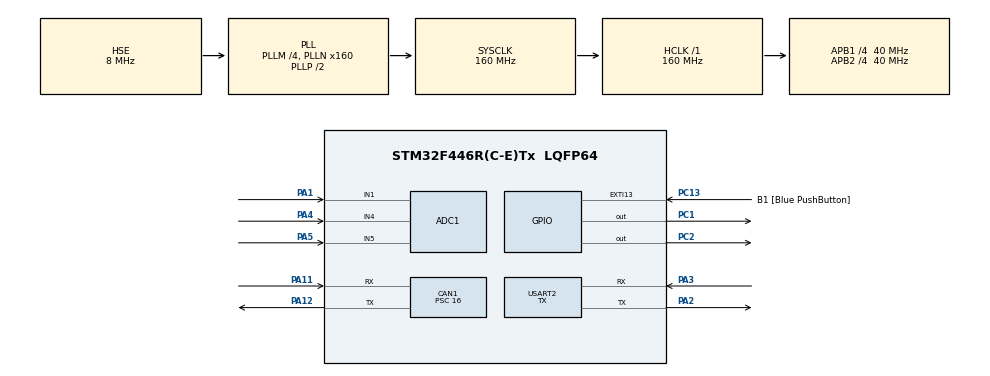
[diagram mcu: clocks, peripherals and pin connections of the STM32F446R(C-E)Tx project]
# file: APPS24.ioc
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ADC1.Channel-0\#ChannelRegularConversion=ADC_CHANNEL_1
ADC1.NbrOfConversionFlag=1
ADC1.Rank-0\#ChannelRegularConversion=1
ADC1.SamplingTime-0\#ChannelRegularConversion=ADC_SAMPLETIME_3CYCLES
ADC1.master=1
CAN1.BS1=CAN_BS1_1TQ
CAN1.BS2=CAN_BS2_2TQ
CAN1.CalculateBaudRate=625000
CAN1.CalculateTimeBit=1600
CAN1.CalculateTimeQuantum=400.0
CAN1.Prescaler=16
Mcu.Family=STM32F4
Mcu.Name=STM32F446R(C-E)Tx
Mcu.Package=LQFP64
NVIC.CAN1_RX0_IRQn=true\:0\:0\:false\:false\:true\:true\:true\:true
NVIC.CAN1_RX1_IRQn=true\:0\:0\:false\:false\:true\:true\:true\:true
NVIC.PriorityGroup=NVIC_PRIORITYGROUP_4
PA1.Signal=ADCx_IN1
PA11.Mode=CAN_Activate
PA11.Signal=CAN1_RX
PA12.Mode=CAN_Activate
PA12.Signal=CAN1_TX
PA13.Mode=Serial_Wire
PA13.Signal=SYS_JTMS-SWDIO
PA14.Mode=Serial_Wire
PA14.Signal=SYS_JTCK-SWCLK
PA2.Mode=Asynchronous
PA2.Signal=USART2_TX
PA3.Mode=Asynchronous
PA3.Signal=USART2_RX
PA4.Signal=ADCx_IN4
PA5.Signal=ADCx_IN5
PC1.Signal=GPIO_Output
PC13.GPIO_Label=B1 [Blue PushButton]
PC13.Signal=GPXTI13
PC14-OSC32_IN.Mode=LSE-External-Oscillator
PC14-OSC32_IN.Signal=RCC_OSC32_IN
PC15-OSC32_OUT.Mode=LSE-External-Oscillator
PC15-OSC32_OUT.Signal=RCC_OSC32_OUT
PC2.Signal=GPIO_Output
PH0-OSC_IN.Mode=HSE-External-Oscillator
PH0-OSC_IN.Signal=RCC_OSC_IN
PH1-OSC_OUT.Mode=HSE-External-Oscillator
PH1-OSC_OUT.Signal=RCC_OSC_OUT
ProjectManager.HeapSize=0x200
ProjectManager.StackSize=0x400
ProjectManager.TargetToolchain=STM32CubeIDE
RCC.AHBFreq_Value=160000000
RCC.APB1CLKDivider=RCC_HCLK_DIV4
RCC.APB1Freq_Value=40000000
RCC.APB1TimFreq_Value=80000000
RCC.APB2CLKDivider=RCC_HCLK_DIV4
RCC.APB2Freq_Value=40000000
RCC.APB2TimFreq_Value=80000000
RCC.CortexFreq_Value=160000000
RCC.HCLKFreq_Value=160000000
RCC.HSE_VALUE=8000000
RCC.PLLM=4
RCC.PLLN=160
RCC.PLLSourceVirtual=RCC_PLLSOURCE_HSE
RCC.SYSCLKFreq_VALUE=160000000
RCC.SYSCLKSource=RCC_SYSCLKSOURCE_PLLCLK
RCC.USBFreq_Value=160000000
RCC.VCOOutputFreq_Value=320000000
SH.ADCx_IN1.0=ADC1_IN1,IN1
SH.ADCx_IN4.0=ADC1_IN4,IN4
SH.ADCx_IN5.0=ADC1_IN5,IN5
USART2.Mode=MODE_TX
USART2.Parity=PARITY_EVEN
USART2.VirtualMode=VM_ASYNC
VP_TIM5_VS_ClockSourceINT.Mode=Internal
board=custom

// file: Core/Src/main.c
/* USER CODE BEGIN Header */
/**
  ******************************************************************************
  * @file           : main.c
  * @brief          : Main program body
  ******************************************************************************
  * @attention
  *
  * Copyright (c) 2023 STMicroelectronics.
  * All rights reserved.
  *
  * This software is licensed under terms that can be found in the LICENSE file
  * in the root directory of this software component.
  * If no LICENSE file comes with this software, it is provided AS-IS.
  *
  ******************************************************************************
  */
/* USER CODE END Header */
#include "main.h"

ADC_HandleTypeDef hadc1;

CAN_HandleTypeDef hcan1;

TIM_HandleTypeDef htim5;

UART_HandleTypeDef huart2;

void SystemClock_Config(void);
static void MX_GPIO_Init(void);
static void MX_USART2_UART_Init(void);
static void MX_CAN1_Init(void);
static void MX_ADC1_Init(void);
static void MX_TIM5_Init(void);

int main(void)
{

  /* MCU Configuration--------------------------------------------------------*/

  /* Reset of all peripherals, Initializes the Flash interface and the Systick. */
  HAL_Init();

  /* Configure the system clock */
  SystemClock_Config();

  /* Initialize all configured peripherals */
  MX_GPIO_Init();
  MX_USART2_UART_Init();
  MX_CAN1_Init();
  MX_ADC1_Init();
  MX_TIM5_Init();
  /* USER CODE BEGIN 2 */
  FEB_Main_User2();
  /* USER CODE END 2 */

  /* Infinite loop */
  while (1)
  {

    /* USER CODE BEGIN 3 */
	//ready to drive
	FEB_Main_User3();
  }
  /* USER CODE END 3 */
}

void SystemClock_Config(void)
{
  RCC_OscInitTypeDef RCC_OscInitStruct = {0};
  RCC_ClkInitTypeDef RCC_ClkInitStruct = {0};

  /** Configure the main internal regulator output voltage
  */
  __HAL_RCC_PWR_CLK_ENABLE();
  __HAL_PWR_VOLTAGESCALING_CONFIG(PWR_REGULATOR_VOLTAGE_SCALE1);

  /** Initializes the RCC Oscillators according to the specified parameters
  * in the RCC_OscInitTypeDef structure.
  */
  RCC_OscInitStruct.OscillatorType = RCC_OSCILLATORTYPE_HSE;
  RCC_OscInitStruct.HSEState = RCC_HSE_ON;
  RCC_OscInitStruct.PLL.PLLState = RCC_PLL_ON;
  RCC_OscInitStruct.PLL.PLLSource = RCC_PLLSOURCE_HSE;
  RCC_OscInitStruct.PLL.PLLM = 4;
  RCC_OscInitStruct.PLL.PLLN = 160;
  RCC_OscInitStruct.PLL.PLLP = RCC_PLLP_DIV2;
  RCC_OscInitStruct.PLL.PLLQ = 2;
  RCC_OscInitStruct.PLL.PLLR = 2;
  if (HAL_RCC_OscConfig(&RCC_OscInitStruct) != HAL_OK)
  {
    Error_Handler();
  }

  /** Initializes the CPU, AHB and APB buses clocks
  */
  RCC_ClkInitStruct.ClockType = RCC_CLOCKTYPE_HCLK|RCC_CLOCKTYPE_SYSCLK
                              |RCC_CLOCKTYPE_PCLK1|RCC_CLOCKTYPE_PCLK2;
  RCC_ClkInitStruct.SYSCLKSource = RCC_SYSCLKSOURCE_PLLCLK;
  RCC_ClkInitStruct.AHBCLKDivider = RCC_SYSCLK_DIV1;
  RCC_ClkInitStruct.APB1CLKDivider = RCC_HCLK_DIV4;
  RCC_ClkInitStruct.APB2CLKDivider = RCC_HCLK_DIV4;

  if (HAL_RCC_ClockConfig(&RCC_ClkInitStruct, FLASH_LATENCY_5) != HAL_OK)
  {
    Error_Handler();
  }
}

static void MX_ADC1_Init(void)
{

  ADC_ChannelConfTypeDef sConfig = {0};

  /** Configure the global features of the ADC (Clock, Resolution, Data Alignment and number of conversion)
  */
  hadc1.Instance = ADC1;
  hadc1.Init.ClockPrescaler = ADC_CLOCK_SYNC_PCLK_DIV2;
  hadc1.Init.Resolution = ADC_RESOLUTION_12B;
  hadc1.Init.ScanConvMode = DISABLE;
  hadc1.Init.ContinuousConvMode = DISABLE;
  hadc1.Init.DiscontinuousConvMode = DISABLE;
  hadc1.Init.ExternalTrigConvEdge = ADC_EXTERNALTRIGCONVEDGE_NONE;
  hadc1.Init.ExternalTrigConv = ADC_SOFTWARE_START;
  hadc1.Init.DataAlign = ADC_DATAALIGN_RIGHT;
  hadc1.Init.NbrOfConversion = 1;
  hadc1.Init.DMAContinuousRequests = DISABLE;
  hadc1.Init.EOCSelection = ADC_EOC_SINGLE_CONV;
  if (HAL_ADC_Init(&hadc1) != HAL_OK)
  {
    Error_Handler();
  }

  /** Configure for the selected ADC regular channel its corresponding rank in the sequencer and its sample time.
  */
  sConfig.Channel = ADC_CHANNEL_1;
  sConfig.Rank = 1;
  sConfig.SamplingTime = ADC_SAMPLETIME_3CYCLES;
  if (HAL_ADC_ConfigChannel(&hadc1, &sConfig) != HAL_OK)
  {
    Error_Handler();
  }

}

static void MX_CAN1_Init(void)
{

  hcan1.Instance = CAN1;
  hcan1.Init.Prescaler = 16;
  hcan1.Init.Mode = CAN_MODE_NORMAL;
  hcan1.Init.SyncJumpWidth = CAN_SJW_1TQ;
  hcan1.Init.TimeSeg1 = CAN_BS1_1TQ;
  hcan1.Init.TimeSeg2 = CAN_BS2_2TQ;
  hcan1.Init.TimeTriggeredMode = DISABLE;
  hcan1.Init.AutoBusOff = DISABLE;
  hcan1.Init.AutoWakeUp = DISABLE;
  hcan1.Init.AutoRetransmission = DISABLE;
  hcan1.Init.ReceiveFifoLocked = DISABLE;
  hcan1.Init.TransmitFifoPriority = DISABLE;
  if (HAL_CAN_Init(&hcan1) != HAL_OK)
  {
    Error_Handler();
  }

}

static void MX_TIM5_Init(void)
{

  TIM_ClockConfigTypeDef sClockSourceConfig = {0};
  TIM_MasterConfigTypeDef sMasterConfig = {0};

  htim5.Instance = TIM5;
  htim5.Init.Prescaler = 0;
  htim5.Init.CounterMode = TIM_COUNTERMODE_UP;
  htim5.Init.Period = 4294967295;
  htim5.Init.ClockDivision = TIM_CLOCKDIVISION_DIV1;
  htim5.Init.AutoReloadPreload = TIM_AUTORELOAD_PRELOAD_DISABLE;
  if (HAL_TIM_Base_Init(&htim5) != HAL_OK)
  {
    Error_Handler();
  }
  sClockSourceConfig.ClockSource = TIM_CLOCKSOURCE_INTERNAL;
  if (HAL_TIM_ConfigClockSource(&htim5, &sClockSourceConfig) != HAL_OK)
  {
    Error_Handler();
  }
  sMasterConfig.MasterOutputTrigger = TIM_TRGO_RESET;
  sMasterConfig.MasterSlaveMode = TIM_MASTERSLAVEMODE_DISABLE;
  if (HAL_TIMEx_MasterConfigSynchronization(&htim5, &sMasterConfig) != HAL_OK)
  {
    Error_Handler();
  }

}

static void MX_USART2_UART_Init(void)
{

  huart2.Instance = USART2;
  huart2.Init.BaudRate = 115200;
  huart2.Init.WordLength = UART_WORDLENGTH_8B;
  huart2.Init.StopBits = UART_STOPBITS_1;
  huart2.Init.Parity = UART_PARITY_EVEN;
  huart2.Init.Mode = UART_MODE_TX;
  huart2.Init.HwFlowCtl = UART_HWCONTROL_NONE;
  huart2.Init.OverSampling = UART_OVERSAMPLING_16;
  if (HAL_UART_Init(&huart2) != HAL_OK)
  {
    Error_Handler();
  }

}

static void MX_GPIO_Init(void)
{
  GPIO_InitTypeDef GPIO_InitStruct = {0};

  /* GPIO Ports Clock Enable */
  __HAL_RCC_GPIOC_CLK_ENABLE();
  __HAL_RCC_GPIOH_CLK_ENABLE();
  __HAL_RCC_GPIOA_CLK_ENABLE();

  /*Configure GPIO pin Output Level */
  HAL_GPIO_WritePin(GPIOC, GPIO_PIN_1|GPIO_PIN_2, GPIO_PIN_RESET);

  /*Configure GPIO pin : B1_Pin */
  GPIO_InitStruct.Pin = B1_Pin;
  GPIO_InitStruct.Mode = GPIO_MODE_IT_RISING;
  GPIO_InitStruct.Pull = GPIO_NOPULL;
  HAL_GPIO_Init(B1_GPIO_Port, &GPIO_InitStruct);

  /*Configure GPIO pins : PC1 PC2 */
  GPIO_InitStruct.Pin = GPIO_PIN_1|GPIO_PIN_2;
  GPIO_InitStruct.Mode = GPIO_MODE_OUTPUT_PP;
  GPIO_InitStruct.Pull = GPIO_NOPULL;
  GPIO_InitStruct.Speed = GPIO_SPEED_FREQ_LOW;
  HAL_GPIO_Init(GPIOC, &GPIO_InitStruct);

}

void Error_Handler(void)
{
  __disable_irq();
  while (1)
  {
  }
}
